# STM32F413CGU3 register map
File version: 1.0
Registers are 32-bit, access not given, reset 0x0 unless marked. A register's access mark holds for its fields unless they carry their own. Offsets are from the block's base; [hi:lo] are bit positions; {n}, {i} and the like mark numbered series.

## DFSDM1
Base 0x40016000
Same registers: DFSDM2 0x40016400
0x00 CH0CFGR1
  [31] DFSDMEN, [30] CKOUTSRC, [23:16] CKOUTDIV, [15:14] DATPACK, [13:12] DATMPX, [8] CHINSEL, [7] CHEN, [6] CKABEN, [5] SCDEN, [29:4] s, [3:2] SPICKSEL, [1:0] SITP
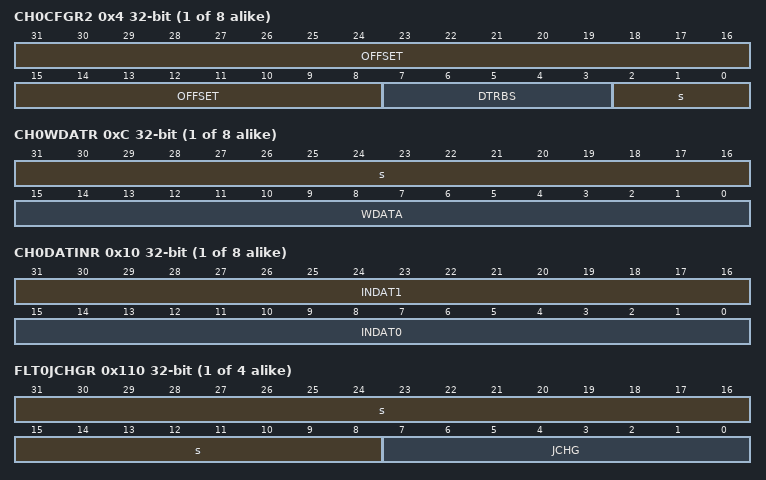
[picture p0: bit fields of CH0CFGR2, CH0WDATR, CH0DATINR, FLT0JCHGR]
{0x4+0x20*i} CH{i}CFGR2 (i=0..7)
  [31:8] OFFSET, [7:3] DTRBS, [2:0] s
{0x8+0x20*i} CH{i}AWSCDR (i=0..7)
  [23:22] AWFORD, [20:16] AWFOSR, [15:12] BKSCD, [31:8] s, [7:0] SCDT
{0xC+0x20*i} CH{i}WDATR (i=0..7)
  [31:16] s, [15:0] WDATA
{0x10+0x20*i} CH{i}DATINR (i=0..7)
  [31:16] INDAT1, [15:0] INDAT0
{0x0+0x20*i} CH{i}CFGR1 (i=1..7)
  [15:14] DATPACK, [13:12] DATMPX, [8] CHINSEL, [7] CHEN, [6] CKABEN, [5] SCDEN, [31:4] s, [3:2] SPICKSEL, [1:0] SITP
{0x100+0x80*i} FLT{i}CR1 (i=0..3)
  [30] AWFSEL, [29] FAST, [26:24] RCH, [21] RDMAEN, [19] RSYNC, [18] RCONT, [17] RSWSTART, [14:13] JEXTEN, [10:8] JEXTSEL, [5] JDMAEN, [4] JSCAN, [3] JSYNC, [31:2] s, [1] JSWSTART, [0] DFEN
0x104 FLT0CR2
  [23:16] AWDCH, [15:8] EXCH, [31:7] s, [6] CKABIE, [5] SCDIE, [4] AWDIE, [3] ROVRIE, [2] JOVRIE, [1] REOCIE, [0] JEOCIE
0x108 FLT0ISR
  [31:24] SCDF, [23:16] CKABF, [14] RCIP, [13] JCIP, [15:5] s, [4] AWDF, [3] ROVRF, [2] JOVRF, [1] REOCF, [0] JEOCF
0x10C FLT0ICR
  [31:24] CLRSCDF, [23:16] CLRCKABF, [3] CLRROVRF, [2] CLRJOVRF, [15:0] s
{0x110+0x80*i} FLT{i}JCHGR (i=0..3)
  [31:8] s, [7:0] JCHG
{0x114+0x80*i} FLT{i}FCR (i=0..3)
  [31:29] FORD, [25:16] FOSR, [28:8] s, [7:0] IOSR
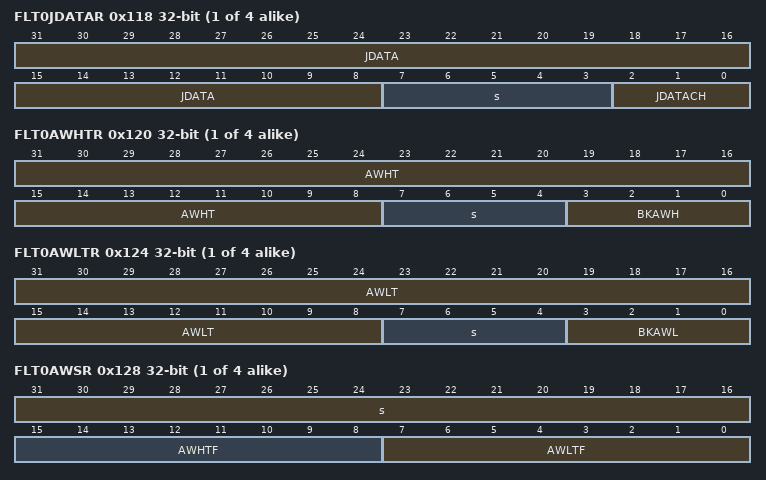
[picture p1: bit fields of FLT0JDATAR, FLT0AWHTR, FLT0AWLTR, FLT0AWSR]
{0x118+0x80*i} FLT{i}JDATAR (i=0..3)
  [31:8] JDATA, [7:3] s, [2:0] JDATACH
{0x11C+0x80*i} FLT{i}RDATAR (i=0..3)
  [31:8] RDATA, [4] RPEND, [7:3] s, [2:0] RDATACH
{0x120+0x80*i} FLT{i}AWHTR (i=0..3)
  [31:8] AWHT, [7:4] s, [3:0] BKAWH
{0x124+0x80*i} FLT{i}AWLTR (i=0..3)
  [31:8] AWLT, [7:4] s, [3:0] BKAWL
{0x128+0x80*i} FLT{i}AWSR (i=0..3)
  [31:16] s, [15:8] AWHTF, [7:0] AWLTF
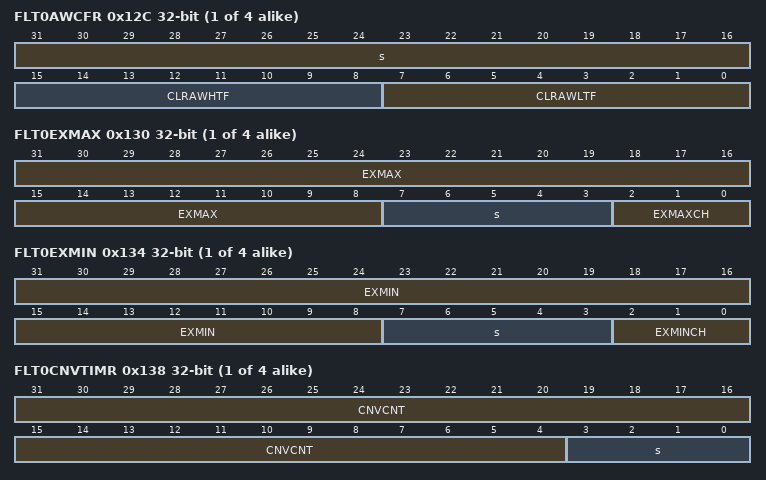
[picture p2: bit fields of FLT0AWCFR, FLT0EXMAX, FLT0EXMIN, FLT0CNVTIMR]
{0x12C+0x80*i} FLT{i}AWCFR (i=0..3)
  [31:16] s, [15:8] CLRAWHTF, [7:0] CLRAWLTF
{0x130+0x80*i} FLT{i}EXMAX (i=0..3)
  [31:8] EXMAX, [7:3] s, [2:0] EXMAXCH
{0x134+0x80*i} FLT{i}EXMIN (i=0..3)
  [31:8] EXMIN, [7:3] s, [2:0] EXMINCH
{0x138+0x80*i} FLT{i}CNVTIMR (i=0..3)
  [31:4] CNVCNT, [3:0] s
{0x104+0x80*i} FLT{i}CR2 (i=1..3)
  [23:16] AWDCH, [15:8] EXCH, [31:5] s, [4] AWDIE, [3] ROVRIE, [2] JOVRIE, [1] REOCIE, [0] JEOCIE
{0x108+0x80*i} FLT{i}ISR (i=1..3)
  [14] RCIP, [13] JCIP, [31:5] s, [4] AWDF, [3] ROVRF, [2] JOVRF, [1] REOCF, [0] JEOCF
{0x10C+0x80*i} FLT{i}ICR (i=1..3)
  [3] CLRROVRF, [2] CLRJOVRF, [31:0] s

## GPIOA
Base 0x40020000
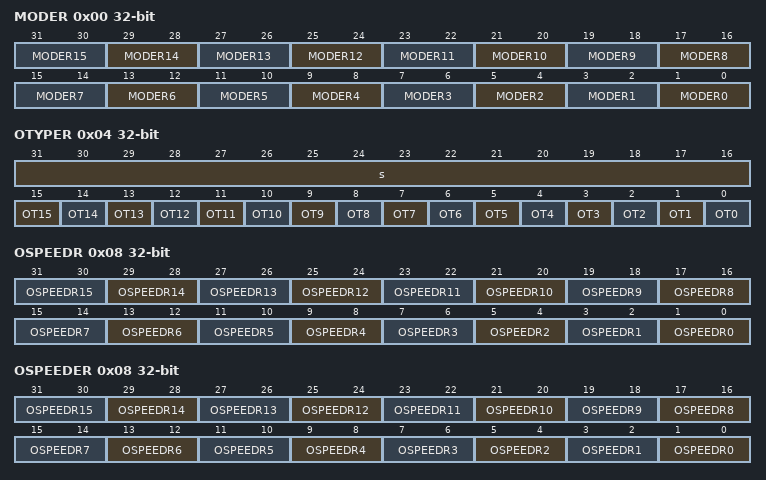
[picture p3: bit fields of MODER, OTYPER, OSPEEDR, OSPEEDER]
0x00 MODER
  [2n+1:2n] MODER{n} (n=0..15)
0x04 OTYPER
  [31:16] s, [n] OT{n} (n=0..15)
0x08 OSPEEDR
  [2n+1:2n] OSPEEDR{n} (n=0..15)
0x08 OSPEEDER
  [2n+1:2n] OSPEEDR{n} (n=0..15)
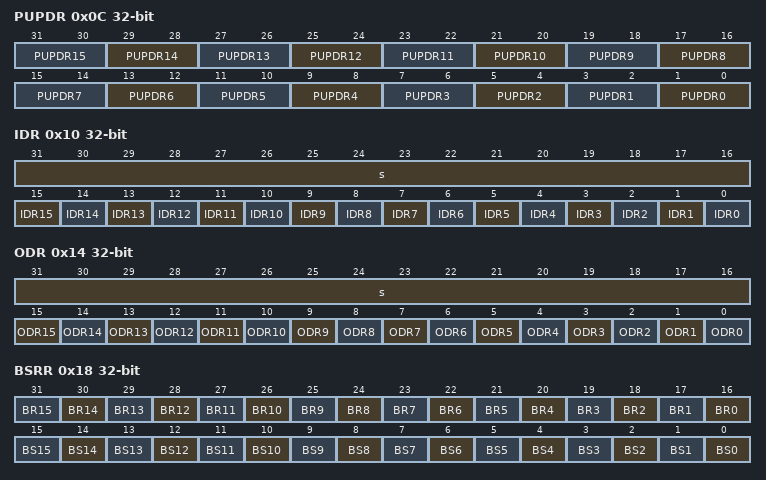
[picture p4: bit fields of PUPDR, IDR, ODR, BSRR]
0x0C PUPDR
  [2n+1:2n] PUPDR{n} (n=0..15)
0x10 IDR
  [31:16] s, [n] IDR{n} (n=0..15)
0x14 ODR
  [31:16] s, [n] ODR{n} (n=0..15)
0x18 BSRR
  [n+16] BR{n} (n=0..15), [n] BS{n} (n=0..15)
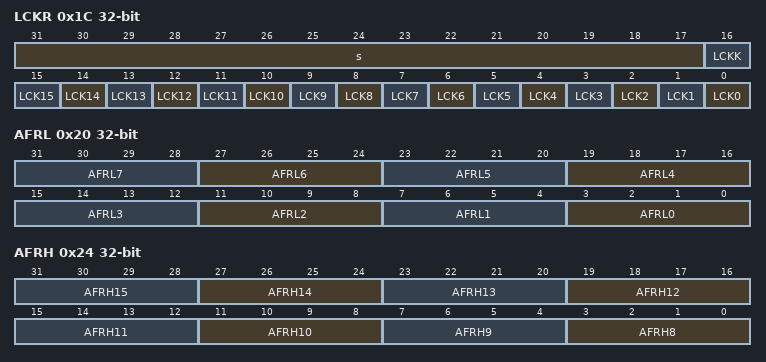
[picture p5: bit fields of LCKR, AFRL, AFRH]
0x1C LCKR
  [31:17] s, [16] LCKK, [n] LCK{n} (n=0..15)
0x20 AFRL
  [4n+3:4n] AFRL{n} (n=0..7)
0x24 AFRH
  [4n-29:4n-32] AFRH{n} (n=8..15)

## GPIOB
Base 0x40020400
Registers as GPIOA, without OSPEEDER.

## GPIOC
Base 0x40020800
Registers as GPIOA, without OSPEEDER.

## GPIOD
Base 0x40020C00
Registers as GPIOA, without OSPEEDER.

## GPIOE
Base 0x40021000
Registers as GPIOA, without OSPEEDER.

## GPIOF
Base 0x40021400
Registers as GPIOA, without OSPEEDER.

## GPIOG
Base 0x40021800
Registers as GPIOA, without OSPEEDER.

## GPIOH
Base 0x40021C00
Registers as GPIOA, without OSPEEDER.

## CRC
Base 0x40023000
0x00 DR
  [31:0] DATA
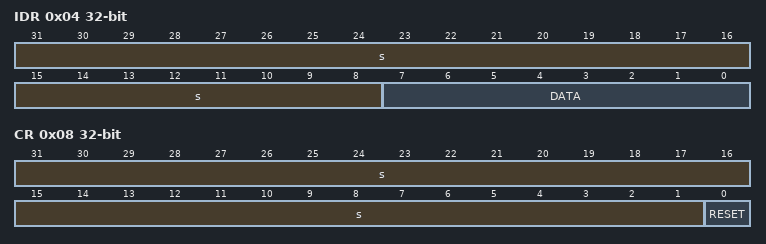
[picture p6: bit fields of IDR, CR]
0x04 IDR
  [31:8] s, [7:0] DATA
0x08 CR
  [31:1] s, [0] RESET

## FLASH
Base 0x40023C00
0x00 ACR
  [12] DCRST, [11] ICRST, [10] DCEN, [9] ICEN, [8] PRFTEN, [31:4] s, [3:0] LATENCY
0x04 KEYR
  [31:0] KEY
0x08 OPTKEYR
0x0C SR
  [16] BSY, [8] RDERR, [7] PGSERR, [6] PGPERR, [5] PGAERR, [4] WRPERR, [31:2] s, [1] OPERR, [0] EOP
0x10 CR
  [31] LOCK, [25] ERRIE, [24] EOPIE, [16] STRT, [9:8] PSIZE, [30:7] s, [6:3] SNB, [2] MER, [1] SER, [0] PG
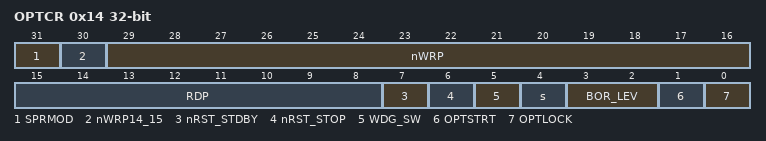
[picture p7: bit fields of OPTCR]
0x14 OPTCR
  [31] SPRMOD, [30] nWRP14_15, [29:16] nWRP, [15:8] RDP, [7] nRST_STDBY, [6] nRST_STOP, [5] WDG_SW, [4] s, [3:2] BOR_LEV, [1] OPTSTRT, [0] OPTLOCK
